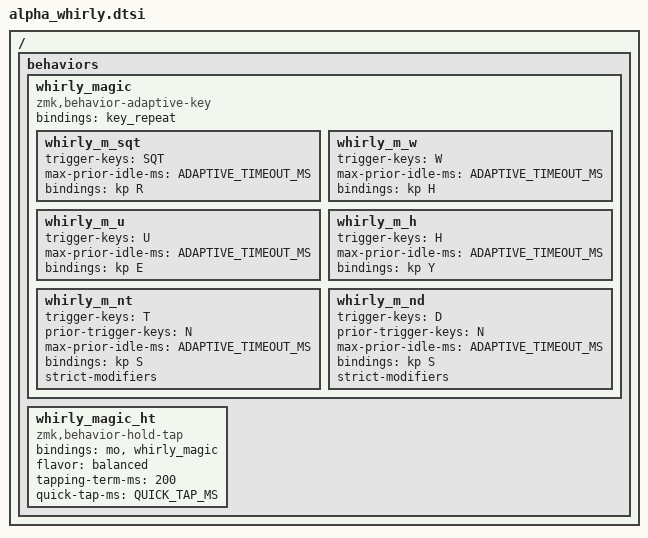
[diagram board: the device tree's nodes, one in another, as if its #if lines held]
/* Whirly — whirl variant with y on the left index. Inactive by default. */

/* >>> generated adaptive swaps (do not edit — run ./scripts/generate) >>> */
#include "../generated/alpha_whirly.dtsi"
/* <<< end generated adaptive swaps <<< */

/* Repeat-magic thumb (hand-written; not a two-letter swap). */
#if WHIRLY_ADAPTIVE
ZMK_ADAPTIVE_KEY(whirly_magic, bindings = <&key_repeat>;
    whirly_m_sqt { trigger-keys = <SQT>; max-prior-idle-ms = <ADAPTIVE_TIMEOUT_MS>; bindings = <&kp R>; };
    whirly_m_w   { trigger-keys = <W>;   max-prior-idle-ms = <ADAPTIVE_TIMEOUT_MS>; bindings = <&kp H>; };
    whirly_m_u   { trigger-keys = <U>;   max-prior-idle-ms = <ADAPTIVE_TIMEOUT_MS>; bindings = <&kp E>; };
    whirly_m_h   { trigger-keys = <H>;   max-prior-idle-ms = <ADAPTIVE_TIMEOUT_MS>; bindings = <&kp Y>; };
    whirly_m_nt  { trigger-keys = <T>; prior-trigger-keys = <N>; max-prior-idle-ms = <ADAPTIVE_TIMEOUT_MS>; bindings = <&kp S>; strict-modifiers; };
    whirly_m_nd  { trigger-keys = <D>; prior-trigger-keys = <N>; max-prior-idle-ms = <ADAPTIVE_TIMEOUT_MS>; bindings = <&kp S>; strict-modifiers; };
)
ZMK_HOLD_TAP(whirly_magic_ht, bindings = <&mo>, <&whirly_magic>;
             flavor = "balanced"; tapping-term-ms = <200>;
             quick-tap-ms = <QUICK_TAP_MS>;)
#define WHIRLY_MAGIC &whirly_magic_ht LAYER_Num 0
#endif

#ifndef WHIRLY_C
#define WHIRLY_C &kp C
#endif
#ifndef WHIRLY_D
#define WHIRLY_D &kp D
#endif
#ifndef WHIRLY_G
#define WHIRLY_G &kp G
#endif
#ifndef WHIRLY_H
#define WHIRLY_H &hml LSHFT H
#endif
#ifndef WHIRLY_L
#define WHIRLY_L &kp L
#endif
#ifndef WHIRLY_P
#define WHIRLY_P &kp P
#endif
#ifndef WHIRLY_S
#define WHIRLY_S &hml LALT S
#endif
#ifndef WHIRLY_X
#define WHIRLY_X &kp X
#endif
#ifndef WHIRLY_MAGIC
#define WHIRLY_MAGIC &num_repeat LAYER_Num 0
#endif

ZMK_BASE_LAYER(Whirly,
//╭──────────┬──────────┬──────────┬──────────┬──────────╮   ╭──────────┬──────────┬──────────┬──────────┬──────────╮
    &kp B      WHIRLY_C   WHIRLY_D   &kp W      &kp K      ,  &kp Q      WHIRLY_L   &kp U      &kp O      &kp J      ,
//├──────────┼──────────┼──────────┼──────────┼──────────┤   ├──────────┼──────────┼──────────┼──────────┼──────────┤
   &hml LGUI N WHIRLY_S   &hml LCTRL T WHIRLY_H &kp Y , &sqt_dqt   &hmr RSHFT R &hmr RCTRL E &hmr RALT A &hmr RGUI I ,
//├──────────┼──────────┼──────────┼──────────┼──────────┤   ├──────────┼──────────┼──────────┼──────────┼──────────┤
    WHIRLY_P   WHIRLY_G   &kp M      &kp F      &kp V      ,  &kp Z      WHIRLY_X   &comma_excl &dot_qmark &kp SEMI ,
//╰──────────┴──────────┴──────────┼──────────┼──────────┤   ├──────────┼──────────┼──────────┴──────────┴──────────╯
        LH_NONE &thumb_bspc LAYER_Nav 0  &thumb_spc LAYER_Symbol SPACE , WHIRLY_MAGIC  &sk LSHFT RH_NONE
//                                 ╰──────────┴──────────╯   ╰──────────┴──────────╯
)
